# MDR1206AFI register map
Vendor: Milandr; File version: 2.0
CPU: BM-310S0, little endian
Registers are 32-bit, read-write, reset 0x0 unless marked. A register's access mark holds for its fields unless they carry their own. Offsets are from the block's base; [hi:lo] are bit positions; {n}, {i} and the like mark numbered series; 'fields as' and 'values as' point back to an identical list.

## ADCUI — ADCUI CONTROLLER
Base 0x50068000
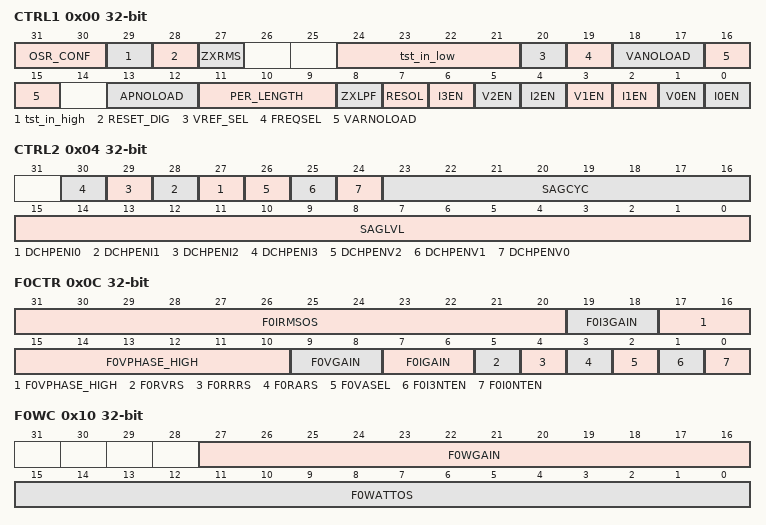
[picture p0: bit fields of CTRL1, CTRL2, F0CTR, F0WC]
0x00 CTRL1 — Control Register 1
  [31:30] OSR_CONF — Oversample rate
    0=1024; 1=512; 2=256
  [29] tst_in_high — Test. Always write as zero
  [28] RESET_DIG — Resets the digital units of ADCUI
    0=NO_RESET; 1=RESET
  [27] ZXRMS — Updating of the RMS registers
  [24:21] tst_in_low — Test. Always write as zero
  [20] VREF_SEL — Reference voltage selection
    0=EXT (Voltage from VREF input); 1=INT (Internal reference voltage 2.4V)
  [19] FREQSEL — Calculation of the period lenght in the V-channels
    0=STORE (The last calculated value is stored); 1=CALC_EN
  [18:17] VANOLOAD — "Without load" mode when total energy is calculated
  [16:15] VARNOLOAD — "Without load" mode when reactive-phase energy is calculated
  [13:12] APNOLOAD — "Without load" mode when active energy is calculated
  [11:9] PER_LENGTH — The range of the period and phase shift calculation
  [8] ZXLPF — Disabling of the LPF before cross-zero detector in the V-channels
    0=LPF_ON; 1=LPF_OFF
  [7] RESOL — OUTPUT_MODE
    0=16_BITS; 1=24_BITS
  [2n] I{n}EN (n=0..3) — Enables channel I{n}
  [5] V2EN — Enables channel V2
  [3] V1EN — Enables channel V1
  [1] V0EN — Enables channel V0
0x04 CTRL2 — Control Register 2
  [n+27] DCHPENI{n} (n=0..3) — Enables chopper for channel I{n}
  [26] DCHPENV2 — Enables chopper for channel V2
  [25] DCHPENV1 — Enables chopper for channel V1
  [24] DCHPENV0 — Enables chopper for channel V0
  [23:16] SAGCYC — The number of half-cycles of U for voltage slump calculation
  [15:0] SAGLVL — The allowed voltage slump level
0x08 CTRL3 — Control Register 3
  [11:0] ZXTOUT — Time in clock cycles when there was no zero crossing
0x0C F0CTR — F0 Control Register
  [31:20] F0IRMSOS — Shift calibration for I0 RMS calculator
  [19:18] F0I3GAIN — Preamplifier in the I3 channel
    0=6dB; 1=12dB; 2=18dB; 3=24dB
  [17:10] F0VPHASE_HIGH — Phase shift of V relative to I. In complementary code
  [9:8] F0VGAIN — Preamplifier in the V channel
    0=0dB; 1=6dB; 2=12dB; 3=18dB
  [7:6] F0IGAIN — Preamplifier in the I0 channel
    0=6dB; 1=12dB; 2=18dB; 3=24dB
  [5] F0RVRS wo — Write resets the counter of the transmitted full energy
  [4] F0RRRS wo — Write resets the counter of the transmitted reactive-phase energy
  [3] F0RARS wo — Write resets the counter of the transmitted active-phase energy
  [2] F0VASEL — What to save in the Full Energy Register
    0=Full Energy; 1=I RMS
  [1] F0I3NTEN — Disables the integrator in the I3 channel
    0=ON; 1=OFF
  [0] F0I0NTEN — Disables the integrator in the I0 channel
    0=ON; 1=OFF
0x10 F0WC — Active Energy Calculation in F0
  [27:16] F0WGAIN — Gain calibration of the active power channel
  [15:0] F0WATTOS — Shift calibration of the active power channel
0x14 F0WATTP ro — 32 high-order bits of the 57-bit internal accumulator of the positive active energy
0x18 F0WATTN ro — 32 high-order bits of the 57-bit internal accumulator of the negative active energy
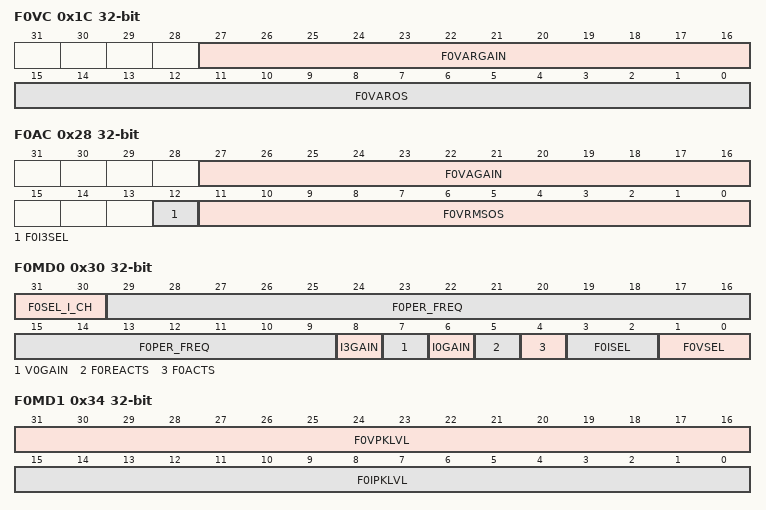
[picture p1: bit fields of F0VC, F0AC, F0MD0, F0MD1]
0x1C F0VC — Reactive Energy Calculation in F0
  [27:16] F0VARGAIN — Gain calibration of the reactive power channel
  [15:0] F0VAROS — Shift calibration of the reactive power channel
0x20 F0VARP ro — Higher-part of the positive reactive energy accumulator in F0
0x24 F0VARN ro — Higher-part of the negative reactive energy accumulator in F0
0x28 F0AC — Full energy calculation in F0
  [27:16] F0VAGAIN — Gain calibration of the full power channel
  [12] F0I3SEL — Data for the FIFO of the I3 channel
    0=AFTER_HPF; 1=BEFORE_HPF
  [11:0] F0VRMSOS — Calibration of the U RMS calculator
{0x2C+0x58*i} F{i}VR ro (i=0..2) — Upper-part of the full energy accumulator in F{i}
0x30 F0MD0 — Parameters 0 for F0
  [31:30] F0SEL_I_CH — Active I-channel for power parameters calculation
    1=I0; 2=I3
  [29:9] F0PER_FREQ ro — Period length of the input signal in the V0-channel
  [8] I3GAIN — Digital gain in I3
    0=NO_GAIN; 1=6dB (Shifts the result by 1 to the left)
  [7] V0GAIN — Digital gain in V0
    0=NO_GAIN; 1=6dB (Shifts the result by 1 to the left)
  [6] I0GAIN — Digital gain in I0
    0=NO_GAIN; 1=6dB (Shifts the result by 1 to the left)
  [5] F0REACTS ro — The sign of the reactive energy in the last period
  [4] F0ACTS ro — The sign of the active energy in the last period
  [3:2] F0ISEL — Data for the FIFO of the I0 channel
    0=I_SAMPLES (Before or after HPF. See F0ISEL_HPF); 1=ACTIVE_POWER_SAMPLES; 2=REACTIVE_POWER_SAMPLES; 3=FULL_POWER_SAMPLES
  [1:0] F0VSEL — Data for the FIFO of the V0 channel
    0=V_SAMPLES (Before HPF); 1=ACTIVE_POWER_SAMPLES; 2=REACTIVE_POWER_SAMPLES; 3=V_HPF_SAMPLES (After HPF)
0x34 F0MD1 — Parameters 1 for F1
  [31:16] F0VPKLVL — V peak level
  [15:0] F0IPKLVL — I peak level
0x38 F0VPEAK — V peak value in F0
  [23:0] F0VPEAK — V peak value
0x3C F0IPEAK — I peak value in F0
  [23:0] F0IPEAK — I peak value
0x40 F0VDAT — FIFO for V-channel samples in F0
  [23:0] F0VDAT ro — V or a P samples FIFO
0x44 F0I0DAT — I0 samples FIFO in F0
  [23:0] F0I0DAT ro — I0 or a P samples FIFO
0x48 F0I3DAT — I3 samples FIFO in F0
  [23:0] F0I3DAT ro — I3 samples FIFO
0x4C F0VRMS — V RMS in F0
  [23:0] F0VRMS ro — V RMS
{0x50+0x58*i} F{i}VRMS2 ro (i=0..2) — V RMS squared in F{i}
0x54 F0IRMS — I RMS in F0
  [23:0] F0IRMS ro
{0x58+0x58*i} F{i}IRMS2 ro (i=0..2) — I RMS squared in F{i}
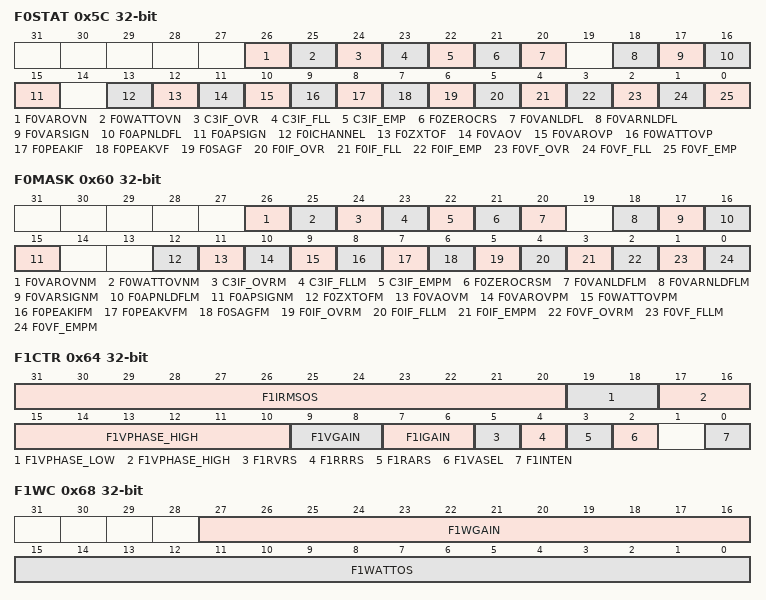
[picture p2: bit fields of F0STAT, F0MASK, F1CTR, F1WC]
0x5C F0STAT — F0 Status Register
  [26] F0VAROVN — Overflow of the negative reactive energy accumulator register. Write as "1" resets this flag
  [25] F0WATTOVN — Overflow of the negative active energy accumulator register. Write as "1" resets this flag
  [24] C3IF_OVR — Overflow of FIFO F0I3DAT
  [23] C3IF_FLL ro — FIFO F0I3DAT is full
  [22] C3IF_EMP ro — FIFO F0I3DAT is empty
  [21] F0ZEROCRS — Zero-crossing in V-channel. Write "1" resets this flag
  [20] F0VANLDFL ro — Full power is less than the comparison level
  [18] F0VARNLDFL ro — Reactive power is less than the comparison level
  [17] F0VARSIGN — Reactive power has changed its sign. Write as "1" resets this flag
  [16] F0APNLDFL ro — Active power is less than the comparison level
  [15] F0APSIGN — Active power has changed its sign. Write as "1" resets this flag
  [13] F0ICHANNEL ro — Active I-channel
    0=I0; 1=I3
  [12] F0ZXTOF — No zero-crossing in V0 during ZXTOUT. Write as "1" resets this flag
  [11] F0VAOV — Overflow of the full energy accumulator register. Write as "1" resets this flag
  [10] F0VAROVP — Overflow of the positive reactive energy accumulator register. Write as "1" resets this flag
  [9] F0WATTOVP — Overflow of the positive active energy accumulator register. Write as "1" resets this flag
  [8] F0PEAKIF — Excess of I threshold. Write as "1" resets this flag
  [7] F0PEAKVF — Excess of V threshold. Write as "1" resets this flag
  [6] F0SAGF — Voltage sag (ADCUI_CTRL2[15:0]) has occurred. Write as "1" resets this flag
  [5] F0IF_OVR — Overflow of FIFO F0IDAT. Write as "1" resets this flag
  [4] F0IF_FLL ro — FIFO F0IDAT is full
  [3] F0IF_EMP ro — FIFO F0IDAT is empty
  [2] F0VF_OVR — Overflow of FIFO F0VDAT. Write as "1" resets this flag
  [1] F0VF_FLL ro — FIFO F0VDAT is full
  [0] F0VF_EMP ro — FIFO F0VDAT is empty
0x60 F0MASK — Mask for interrupts in F0
  [26] F0VAROVNM — MASK: Overflow of the negative reactive energy accumulator register
  [25] F0WATTOVNM — MASK: Overflow of the negative active energy accumulator register
  [24] C3IF_OVRM — MASK: Overflow of FIFO F0I3DAT
  [23] C3IF_FLLM — MASK: FIFO F0I3DAT is full
  [22] C3IF_EMPM — MASK: FIFO F0I3DAT is empty
  [21] F0ZEROCRSM — MASK: Zero-crossing in V-channel
  [20] F0VANLDFLM — MASK: Full power is less than the comparison level
  [18] F0VARNLDFLM — MASK: Reactive power is less than the comparison level
  [17] F0VARSIGNM — MASK: Reactive power has changed its sign
  [16] F0APNLDFLM — MASK: Active power is less than the comparison level
  [15] F0APSIGNM — MASK: Active power has changed its sign
  [12] F0ZXTOFM — MASK: No zero-crossing in V0 during ZXTOUT
  [11] F0VAOVM — MASK: Overflow of the full energy accumulator register
  [10] F0VAROVPM — MASK: Overflow of the positive reactive energy accumulator register
  [9] F0WATTOVPM — MASK: Overflow of the positive active energy accumulator register
  [8] F0PEAKIFM — MASK: Excess of I threshold
  [7] F0PEAKVFM — MASK: Excess of V threshold
  [6] F0SAGFM — MASK: Voltage sag has occurred
  [5] F0IF_OVRM — MASK: Overflow of FIFO F0IDAT
  [4] F0IF_FLLM ro — MASK: FIFO F0IDAT is full
  [3] F0IF_EMPM ro — MASK: FIFO F0IDAT is empty
  [2] F0VF_OVRM — MASK: Overflow of FIFO F0VDAT
  [1] F0VF_FLLM ro — MASK: FIFO F0VDAT is full
  [0] F0VF_EMPM ro — MASK: FIFO F0VDAT is empty
0x64 F1CTR — F1 Control Register
  [31:20] F1IRMSOS — Shift calibration for I1 RMS calculator
  [19:18] F1VPHASE_LOW — F1VPHASE low order bits
  [17:10] F1VPHASE_HIGH — Phase shift of V relative to I. In complementary code
  [9:8] F1VGAIN — Preamplifier in the V channel
    0=0dB; 1=6dB; 2=12dB; 3=18dB
  [7:6] F1IGAIN — Preamplifier in the I channel
    0=6dB; 1=12dB; 2=18dB; 3=24dB
  [5] F1RVRS wo — A "write" in this register resets the counter of the transmitted full energy
  [4] F1RRRS wo — A "write" in this register resets the counter of the transmitted reactive energy
  [3] F1RARS wo — A "write" in this register resets the counter of the transmitted active energy
  [2] F1VASEL — What to save in the Full Energy Register
    0=Full Energy; 1=I RMS
  [0] F1INTEN — Disables the integrator in the I channel
    0=Int_ON; 1=Int_OFF
0x68 F1WC — Active energy calculation in F1
  [27:16] F1WGAIN — Gain calibration
  [15:0] F1WATTOS — Shift calibration
0x6C F1WATTP ro — Upper-part of the positive active energy accumulator in F1
0x70 F1WATTN ro — Upper-part of the negative active energy accumulator in F1
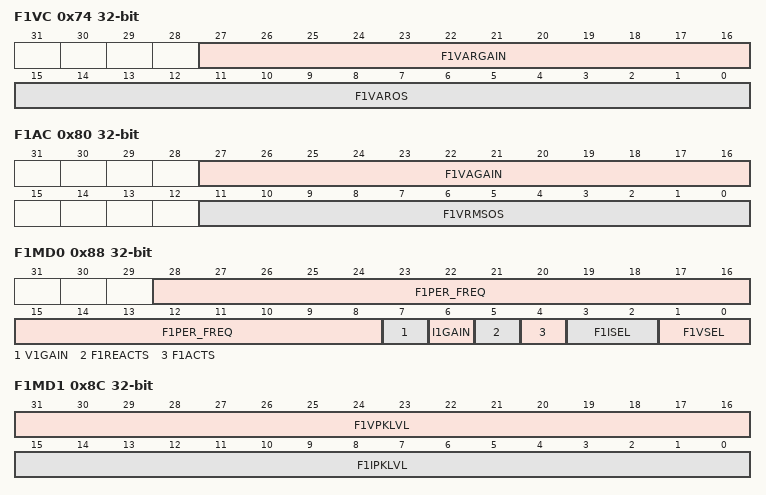
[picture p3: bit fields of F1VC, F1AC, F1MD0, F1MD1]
0x74 F1VC — Reactive energy calculation in F1
  [27:16] F1VARGAIN — Gain calibration
  [15:0] F1VAROS — Shift calibration
0x78 F1VARP ro — Upper-part of the positive reactive energy accumulator in F1
0x7C F1VARN ro — Upper-part of the negative reactive energy accumulator in F1
0x80 F1AC — Full energy calculation in F1
  [27:16] F1VAGAIN — Gain calibration
  [11:0] F1VRMSOS — VRMS calibration
0x88 F1MD0 — Parameters 0 for F1
  [28:8] F1PER_FREQ ro — Period length of the input signal in the V1-channel
  [7] V1GAIN — Digital gain in V1
    0=NO_GAIN; 1=6dB (Shifts the result by 1 to the left)
  [6] I1GAIN — Digital gain in I1
    0=NO_GAIN; 1=6dB (Shifts the result by 1 to the left)
  [5] F1REACTS ro — The sign of the reactive energy in the last period
  [4] F1ACTS ro — The sign of the active energy in the last period
  [3:2] F1ISEL — Data for the FIFO of the I1 channel
    0=I_SAMPLES (Before or after HPF. See F1ISEL_HPF); 1=ACTIVE_POWER_SAMPLES; 2=REACTIVE_POWER_SAMPLES; 3=FULL_POWER_SAMPLES
  [1:0] F1VSEL — Data for the FIFO of the V1 channel
    values as F0MD0.F0VSEL
0x8C F1MD1 — Parameters 1 for F1
  [31:16] F1VPKLVL — V peak level
  [15:0] F1IPKLVL — I peak level
0x90 F1MD2 — Parameters 2 of F1
  [16:0] F1PHASE ro — Phase shift of V1 in regard to V0
0x94 F1VPEAK — V peak value in F1
  [23:0] F1VPEAK — Voltage peak value. A "read" resets the value
0x98 F1IPEAK — I peak value in F1
  [23:0] F1IPEAK — Current peak value. A "read" resets the value
0x9C F1VDAT — FIFO for V-channel samples in F1
  [23:0] F1VDAT ro — V or a P samples FIFO
0xA0 F1IDAT — I samples FIFO in F1
  [23:0] F1IDAT ro — I or a P samples FIFO
0xA4 F1VRMS — V RMS in F1
  [23:0] F1VRMS ro — V RMS
0xAC F1IRMS — I RMS in F1
  [23:0] F1IRMS — I RMS
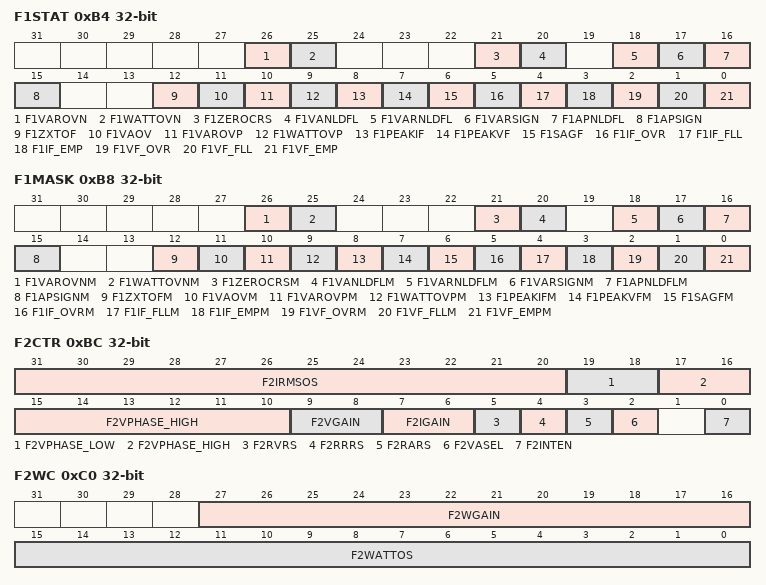
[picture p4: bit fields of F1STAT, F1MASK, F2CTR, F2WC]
0xB4 F1STAT — F1 Status Register
  [26] F1VAROVN — Overflow of the negative reactive energy accumulator register. Write as "1" resets this flag
  [25] F1WATTOVN — Overflow of the negative active energy accumulator register. Write as "1" resets this flag
  [21] F1ZEROCRS — Zero-crossing in V-channel. Write "1" resets this flag
  [20] F1VANLDFL ro — Full power is less than the comparison level
  [18] F1VARNLDFL ro — Reactive power is less than the comparison level
  [17] F1VARSIGN — Reactive power has changed its sign. Write as "1" resets this flag
  [16] F1APNLDFL ro — Active power is less than the comparison level
  [15] F1APSIGN — Active power has changed its sign. Write as "1" resets this flag
  [12] F1ZXTOF — No zero-crossing in V1 during ZXTOUT. Write as "1" resets this flag
  [11] F1VAOV — Overflow of the full energy accumulator register. Write as "1" resets this flag
  [10] F1VAROVP — Overflow of the positive reactive energy accumulator register. Write as "1" resets this flag
  [9] F1WATTOVP — Overflow of the positive active energy accumulator register. Write as "1" resets this flag
  [8] F1PEAKIF — Excess of I threshold. Write as "1" resets this flag
  [7] F1PEAKVF — Excess of V threshold. Write as "1" resets this flag
  [6] F1SAGF — Voltage sag has occurred. Write as "1" resets this flag
  [5] F1IF_OVR — Overflow of FIFO F1IDAT. Write as "1" resets this flag
  [4] F1IF_FLL ro — FIFO F1DAT is full
  [3] F1IF_EMP ro — FIFO F1IDAT is empty
  [2] F1VF_OVR — Overflow of FIFO F1VDAT. Write as "1" resets this flag
  [1] F1VF_FLL ro — FIFO F1VDAT is full
  [0] F1VF_EMP ro — FIFO F1VDAT is empty
0xB8 F1MASK — Mask for interrupts in F1
  [26] F1VAROVNM — MASK: Overflow of the negative reactive energy accumulator
  [25] F1WATTOVNM — MASK: Overflow of the negative active energy accumulator
  [21] F1ZEROCRSM — MASK: Zero-crossing in V-channel
  [20] F1VANLDFLM — MASK: Full power is less than the comparison level
  [18] F1VARNLDFLM — MASK: Reactive power is less than the comparison level
  [17] F1VARSIGNM — MASK: Reactive power has changed its sign
  [16] F1APNLDFLM — MASK: Active power is less than the comparison level
  [15] F1APSIGNM — MASK: Active power has changed its sign
  [12] F1ZXTOFM — MASK: No zero-crossing in V1 during ZXTOUT
  [11] F1VAOVM — MASK: Overflow of the full energy accumulator register
  [10] F1VAROVPM — MASK: Overflow of the positive reactive energy accumulator register
  [9] F1WATTOVPM — MASK: Overflow of the positive active energy accumulator register
  [8] F1PEAKIFM — MASK: Excess of I threshold
  [7] F1PEAKVFM — MASK: Excess of V threshold
  [6] F1SAGFM — MASK: Voltage sag has occurred
  [5] F1IF_OVRM — MASK: Overflow of FIFO F1IDAT
  [4] F1IF_FLLM — MASK: FIFO F1DAT is full
  [3] F1IF_EMPM — MASK: FIFO F1IDAT is empty
  [2] F1VF_OVRM — MASK: Overflow of FIFO F1IDAT
  [1] F1VF_FLLM — MASK: FIFO F1VDAT is full
  [0] F1VF_EMPM — MASK: FIFO F1VDAT is empty
0xBC F2CTR — F2 Control Register
  [31:20] F2IRMSOS — Shift calibration for I2 RMS calculator
  [19:18] F2VPHASE_LOW — F2VPHASE low order bits
  [17:10] F2VPHASE_HIGH — Phase shift of V relative to I. In complementary code
  [9:8] F2VGAIN — Preamplifier in the V channel
    0=0dB; 1=6dB; 2=12dB; 3=18dB
  [7:6] F2IGAIN — Preamplifier in the I channel
    0=6dB; 1=12dB; 2=18dB; 3=24dB
  [5] F2RVRS wo — A "write" in this register resets the counter of the transmitted full energy
  [4] F2RRRS wo — A "write" in this register resets the counter of the transmitted reactive energy
  [3] F2RARS wo — A "write" in this register resets the counter of the transmitted active energy
  [2] F2VASEL — What to save in the Full Energy Register
    0=Full Energy; 1=I RMS
  [0] F2INTEN — Disables the integrator in the I channel
    0=Int_ON; 1=Int_OFF
0xC0 F2WC — Active energy calculation in F2
  [27:16] F2WGAIN — Gain calibration
  [15:0] F2WATTOS — Shift calibration
0xC4 F2WATTP ro — Upper-part of the positive active energy accumulator in F2
0xC8 F2WATTN ro — Upper-part of the negative active energy accumulator in F2
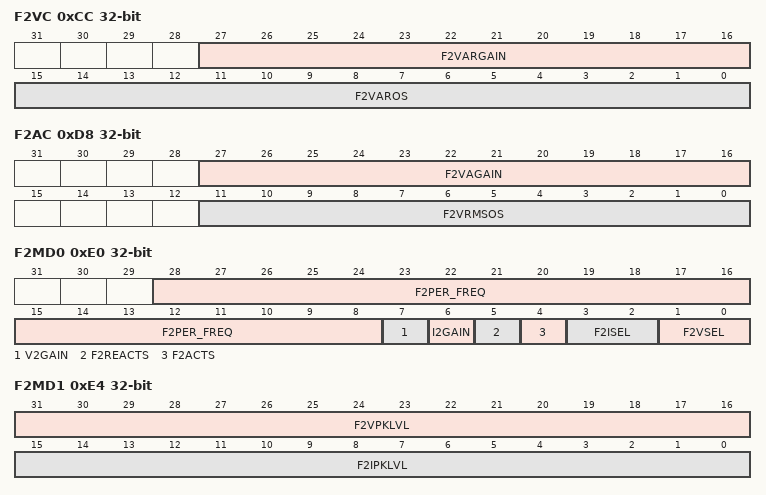
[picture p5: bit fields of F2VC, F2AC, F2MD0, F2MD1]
0xCC F2VC — Reactive energy calculation in F1
  [27:16] F2VARGAIN — Gain calibration
  [15:0] F2VAROS — Shift calibration
0xD0 F2VARP ro — Upper-part of the positive reactive energy accumulator in F2
0xD4 F2VARN ro — Upper-part of the negative reactive energy accumulator in F1
0xD8 F2AC — Full energy calculation in F2
  [27:16] F2VAGAIN — Gain calibration
  [11:0] F2VRMSOS — VRMS calibration
0xE0 F2MD0 — Parameters 0 for F2
  [28:8] F2PER_FREQ ro — Period length of the input signal in the V2-channel
  [7] V2GAIN — Digital gain in V2
    0=NO_GAIN; 1=6dB (Shifts the result by 1 to the left)
  [6] I2GAIN — Digital gain in I2
    0=NO_GAIN; 1=6dB (Shifts the result by 1 to the left)
  [5] F2REACTS ro — The sign of the reactive energy in the last period
  [4] F2ACTS ro — The sign of the active energy in the last period
  [3:2] F2ISEL — Data for the FIFO of the I2 channel
    0=I_SAMPLES (Before or after HPF. See F2ISEL_HPF); 1=ACTIVE_POWER_SAMPLES; 2=REACTIVE_POWER_SAMPLES; 3=FULL_POWER_SAMPLES
  [1:0] F2VSEL — Data for the FIFO of the V2 channel
    values as F0MD0.F0VSEL
0xE4 F2MD1 — Parameters 1 for F2
  [31:16] F2VPKLVL — V peak value
  [15:0] F2IPKLVL — I peak value
0xE8 F2MD2 — Parameters 2 of F2
  [16:0] F2PHASE — Phase shift of V2 in regard to V0
0xEC F2VPEAK — V peak value in F2
  [23:0] F2VPEAK — Voltage peak value. A "read" resets the value
0xF0 F2IPEAK — I peak value in F2
  [23:0] F2IPEAK — Current peak value. A "read" resets the value
0xF4 F2VDAT — FIFO for V-channel samples in F2
  [23:0] F2VDAT — V or a P samples FIFO
0xF8 F2IDAT — I samples FIFO in F2
  [23:0] F2IDAT — I or a P samples FIFO
0xFC F2VRMS — V RMS in F2
  [23:0] F2VRMS — V RMS
0x104 F2IRMS — I RMS in F2
  [23:0] F2IRMS — I RMS
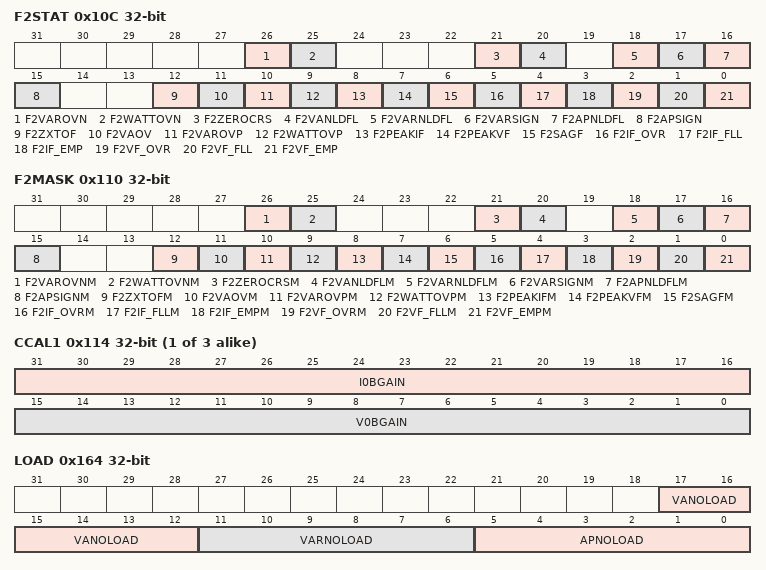
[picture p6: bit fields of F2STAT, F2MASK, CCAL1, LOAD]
0x10C F2STAT — F2 Status Register
  [26] F2VAROVN — Overflow of the negative reactive energy accumulator register. Write as "1" resets this flag
  [25] F2WATTOVN — Overflow of the negative active energy accumulator register. Write as "1" resets this flag
  [21] F2ZEROCRS — Zero-crossing in V-channel. Write "1" resets this flag
  [20] F2VANLDFL ro — Full power is less than the comparison level
  [18] F2VARNLDFL ro — Reactive power is less than the comparison level
  [17] F2VARSIGN — Reactive power has changed its sign. Write as "1" resets this flag
  [16] F2APNLDFL ro — Active power is less than the comparison level
  [15] F2APSIGN — Active power has changed its sign. Write as "1" resets this flag
  [12] F2ZXTOF — No zero-crossing in V2 during ZXTOUT. Write as "1" resets this flag
  [11] F2VAOV — Overflow of the full energy accumulator register. Write as "1" resets this flag
  [10] F2VAROVP — Overflow of the positive reactive energy accumulator register. Write as "1" resets this flag
  [9] F2WATTOVP — Overflow of the positive active energy accumulator register. Write as "1" resets this flag
  [8] F2PEAKIF — Excess of I threshold. Write as "1" resets this flag
  [7] F2PEAKVF — Excess of V threshold. Write as "1" resets this flag
  [6] F2SAGF — Voltage sag has occurred. Write as "1" resets this flag
  [5] F2IF_OVR — Overflow of FIFO F2IDAT. Write as "1" resets this flag
  [4] F2IF_FLL ro — FIFO F2DAT is full
  [3] F2IF_EMP ro — FIFO F2IDAT is empty
  [2] F2VF_OVR — Overflow of FIFO F2VDAT. Write as "1" resets this flag
  [1] F2VF_FLL ro — FIFO F2VDAT is full
  [0] F2VF_EMP ro — FIFO F2VDAT is empty
0x110 F2MASK — Mask for interrupts in F2
  [26] F2VAROVNM — MASK: Overflow of the negative reactive energy accumulator
  [25] F2WATTOVNM — MASK: Overflow of the negative active energy accumulator
  [21] F2ZEROCRSM — MASK: Zero-crossing in V-channel
  [20] F2VANLDFLM — MASK: Full power is less than the comparison level
  [18] F2VARNLDFLM — MASK: Reactive power is less than the comparison level
  [17] F2VARSIGNM — MASK: Reactive power has changed its sign
  [16] F2APNLDFLM — MASK: Active power is less than the comparison level
  [15] F2APSIGNM — MASK: Active power has changed its sign
  [12] F2ZXTOFM — MASK: No zero-crossing in V2 during ZXTOUT
  [11] F2VAOVM — MASK: Overflow of the full energy accumulator register
  [10] F2VAROVPM — MASK: Overflow of the positive reactive energy accumulator register
  [9] F2WATTOVPM — MASK: Overflow of the positive active energy accumulator register
  [8] F2PEAKIFM — MASK: Excess of I threshold
  [7] F2PEAKVFM — MASK: Excess of V threshold
  [6] F2SAGFM — MASK: Voltage sag has occurred
  [5] F2IF_OVRM — MASK: Overflow of FIFO F2IDAT
  [4] F2IF_FLLM — MASK: FIFO F2DAT is full
  [3] F2IF_EMPM — MASK: FIFO F2IDAT is empty
  [2] F2VF_OVRM — MASK: Overflow of FIFO F1IDAT
  [1] F2VF_FLLM — MASK: FIFO F2VDAT is full
  [0] F2VF_EMPM — MASK: FIFO F2VDAT is empty
{0x110+4i} CCAL{i} (i=1..3) — I{i-1} and V{i-1} Calibration Register
  [31:16] I{i-1}BGAIN — Calibration coefficient for I{i-1}
  [15:0] V{i-1}BGAIN — Calibration coefficient for V{i-1}
0x120 CCAL4 — I3 Calibration Register
  [15:0] I3BGAIN — Calibration coefficient for I3
0x124 F0IRMS_INACTIVE — I RMS of an Inactive Channel F0
  [23:0] F0IRMS_INACTIVE ro — I RMS of an inactive channel
{0x128+0x14*i} F{i}WATTP_L (i=0..2) — Lower Part of the Positive Active Energy Accumulator in F{i}
  [24:0] F{i}WATTHRP_L ro — Read after the upper part has been read
{0x12C+0x14*i} F{i}WATTN_L (i=0..2) — Lower Part of the Negative Active Energy Accumulator in F{i}
  [24:0] F{i}WATTHRN_L ro — Read after the upper part has been read
0x130 F0VARP_L — Lower Part of the Positive Reactive Energy Accumulator in F0
  [24:0] F0VARHRP_L ro — Read after the upper part has been read
0x134 F0VARN_L — Lower Part of the Negative Reactive Energy Accumulator in F0
  [24:0] F0VARHRN_L ro — Read after the upper part has been read
0x138 F0VR_L — Lower Part of the Full Energy Accumulator in F0
  [24:0] F0VAHR_L ro — Read after the upper part has been read
0x144 F1VARP_L — Lower Part of the Positive Reactive Energy Accumulator in F1
  [24:0] F1VARHRP_L ro — Read after the upper part has been read
0x148 F1VARN_L — Lower Part of the Negative Reactive Energy Accumulator in F1
  [24:0] F1VARHRN_L ro — Read after the upper part has been read
0x14C F1VR_L — Lower Part of the Full Energy in F1
  [24:0] F1VAHR_L ro — Read after the upper part has been read
0x158 F2VARP_L — Lower Part of the Positive Reactive Energy in F2
  [24:0] F2VARHRP_L ro — Read after the upper part has been read
0x15C F2VARN_L — Lower Part of the Negative Reactive Energy in F2
  [24:0] F2VARHRN_L ro — Read after the upper part has been read
0x160 F2VR_L — Lower Part of the Full Energy in F2
  [24:0] F2VAHR_L ro — Read after the upper part has been read
0x164 LOAD — Control of an Unload Mode
  [17:12] VANOLOAD — An Unload Mode for the full energy calculation
  [11:6] VARNOLOAD — An Unload Mode for the reactive energy calculation
  [5:0] APNOLOAD — An Unload Mode for the active energy calculation
{0x168+4i} F{i}VRMS_TRUE (i=0..2) — An Effective Value of V over a Period in F{i}
  [28:0] F{i}VRMS_TRUE — The value is renewed at V zero-crossing
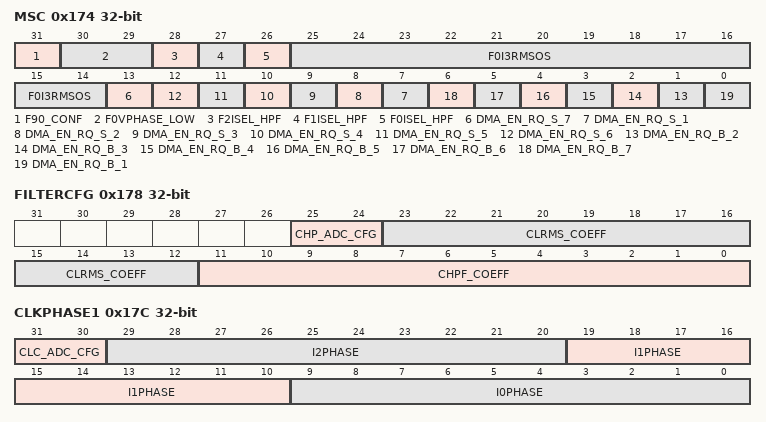
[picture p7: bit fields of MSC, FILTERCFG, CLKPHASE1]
0x174 MSC — DMA Requests and Other Settings
  [31] F90_CONF — Selects V for active and reactive power calculation
    0=Before HPF; 1=After HPF
  [30:29] F0VPHASE_LOW — F0VPHASE[1:0]
  [28] F2ISEL_HPF — Data Written in FIFO F2IDAT
    0=After HPF; 1=Before HPF
  [27] F1ISEL_HPF — Data Written in FIFO F1IDAT
    0=After HPF; 1=Before HPF
  [26] F0ISEL_HPF — Data Written in FIFO F0IDAT
    0=After HPF; 1=Before HPF
  [25:14] F0I3RMSOS — Shift calibration for the I3 RMS calculator
  [13] DMA_EN_RQ_S_7 — Allows channel 6 to make requests to the DMA. Single transactions
  [n+6] DMA_EN_RQ_S_{n} (n=1..6) — Allows channel {n} to make requests to the DMA. Single transactions
  [n-1] DMA_EN_RQ_B_{n} (n=2..7) — Allows channel {n} to make requests to the DMA. Block transactions
  [0] DMA_EN_RQ_B_1 — Allows channel 1 to make requests to the DMA. Block trasactions
0x178 FILTERCFG — Filter configuration Control
  [25:24] CHP_ADC_CFG — Chopper period for all the channels
  [23:12] CLRMS_COEFF — Coefficient for LPF in the RMS Calculation Units which defines a cutoff frequency
  [11:0] CHPF_COEFF — Coefficient for HPF in all channels which defines a cutoff frequency
0x17C CLKPHASE1 — Current Channels Phase Shift Control
  [31:30] CLC_ADC_CFG — ADC clock for all the channels
  [29:20] I2PHASE — Phase shift in I2
  [19:10] I1PHASE — Phase shift in I1
  [9:0] I0PHASE — Phase shift in I0
0x180 CLKPHASE2 — I3 Phase Shift Control
  [9:0] I3PHASE — Phase shift in I3
